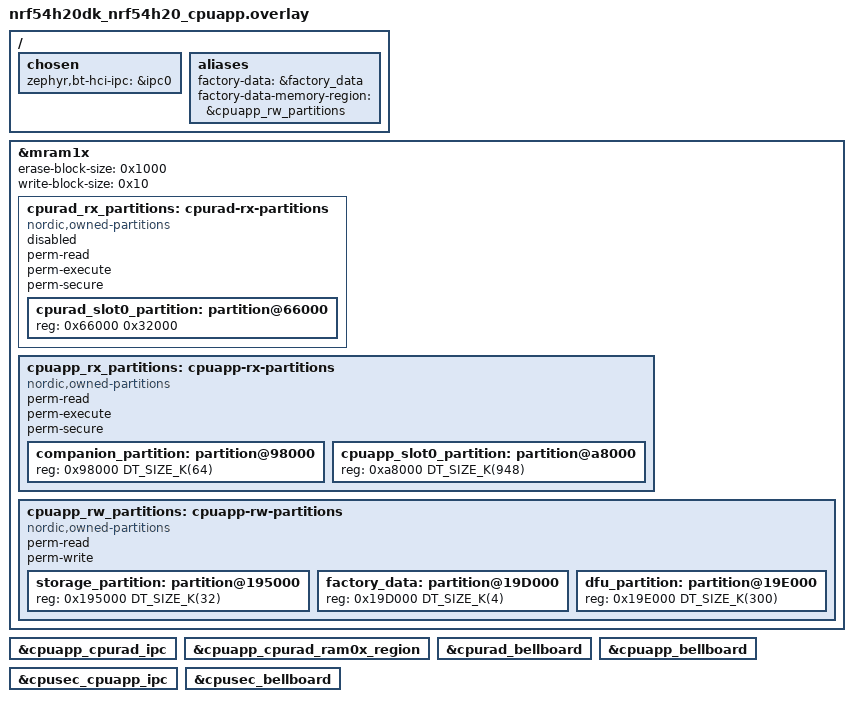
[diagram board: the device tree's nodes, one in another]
/*
 * Copyright (c) 2024 Nordic Semiconductor ASA
 *
 * SPDX-License-Identifier: LicenseRef-Nordic-5-Clause
 */

/ {
	chosen {
		/* prepare IPC to HCI Radio core */
		zephyr,bt-hci-ipc = &ipc0;
	};

	aliases {
		factory-data = &factory_data;
		factory-data-memory-region = &cpuapp_rw_partitions;
	};
};

/**************************************************************
Redefine MRAM memory (Partitions)
**************************************************************/
/* We need to redefine partitions to meet Matter requirements */
/delete-node/ &cpuapp_rx_partitions;
/delete-node/ &cpuapp_rw_partitions;
/delete-node/ &cpurad_rx_partitions;
/delete-node/ &cpuppr_vpr;
/delete-node/ &cpuapp_cpuppr_ipc;

&mram1x {
	erase-block-size = < 0x1000 >;
	write-block-size = < 0x10 >;

	cpurad_rx_partitions: cpurad-rx-partitions {
		compatible = "nordic,owned-partitions", "fixed-partitions";
		status = "disabled";
		perm-read;
		perm-execute;
		perm-secure;
		#address-cells = < 0x1 >;
		#size-cells = < 0x1 >;
		cpurad_slot0_partition: partition@66000 {
			reg = < 0x66000 0x32000 >;
		};
	};

	cpuapp_rx_partitions: cpuapp-rx-partitions {
		compatible = "nordic,owned-partitions", "fixed-partitions";
		status = "okay";
		perm-read;
		perm-execute;
		perm-secure;
		#address-cells = <1>;
		#size-cells = <1>;

		companion_partition: partition@98000 {
			reg = <0x98000 DT_SIZE_K(64)>;
		};

		cpuapp_slot0_partition: partition@a8000 {
			reg = <0xa8000 DT_SIZE_K(948)>;
		};
	};

	cpuapp_rw_partitions: cpuapp-rw-partitions {
		compatible = "nordic,owned-partitions", "fixed-partitions";
		status = "okay";
		perm-read;
		perm-write;
		#address-cells = < 0x1 >;
		#size-cells = < 0x1 >;

		storage_partition: partition@195000 {
			reg = < 0x195000 DT_SIZE_K(32) >;
		};

		factory_data: partition@19D000 {
			reg = < 0x19D000 DT_SIZE_K(4) >;
		};

		dfu_partition: partition@19E000 {
			reg = < 0x19E000 DT_SIZE_K(300) >;
		};

	};
};

/**************************************************************
Enable required peripherals
**************************************************************/
/* Communication between Application and Radio Cores */
ipc0: &cpuapp_cpurad_ipc {
	status = "okay";
};
&cpuapp_cpurad_ram0x_region {
	status = "okay";
};
&cpurad_bellboard {
	status = "okay";
};
&cpuapp_bellboard {
	status = "okay";
};

/* Communication between Application Core and Secure domain for SUIT */
&cpusec_cpuapp_ipc {
	status = "okay";
};
&cpusec_bellboard {
	status = "okay";
};
